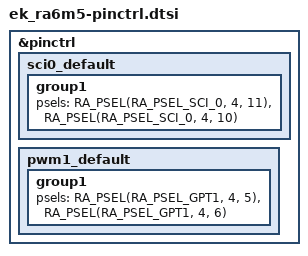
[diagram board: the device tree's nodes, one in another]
/*
 * Copyright (c) 2024 Renesas Electronics Corporation
 * SPDX-License-Identifier: Apache-2.0
 */

&pinctrl {
	sci0_default: sci0_default {
		group1 {
			/* tx rx */
			psels = <RA_PSEL(RA_PSEL_SCI_0, 4, 11)>,
			<RA_PSEL(RA_PSEL_SCI_0, 4, 10)>;
		};
	};

	pwm1_default: pwm1_default {
		group1 {
			/* GTIOC1A GTIOC1B */
			psels = <RA_PSEL(RA_PSEL_GPT1, 4, 5)>,
				<RA_PSEL(RA_PSEL_GPT1, 4, 6)>;
		};
	};
};
